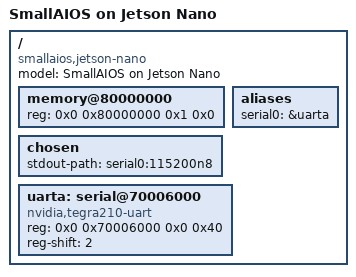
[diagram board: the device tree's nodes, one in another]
// SPDX-License-Identifier: Apache-2.0
// Copyright 2026 SmallAIOS Contributors
//
// Minimal device tree for SmallAIOS on Jetson Nano (Tegra210/T210).
// Written independently from public hardware documentation — NOT derived
// from GPL-licensed Linux kernel or NVIDIA L4T BSP DTS files.
//
// Sources:
//   - ARM Architecture Reference Manual (ARMv8-A)
//   - ARM GIC-400 Technical Reference Manual (ARM IHI 0048B)
//   - ARM Cortex-A57 Technical Reference Manual (ARM DDI 0488)
//   - Jetson Nano Developer Kit carrier board design files (public)
//   - eLinux.org Jetson/Nano wiki

/dts-v1/;

/ {
    compatible = "smallaios,jetson-nano", "nvidia,tegra210";
    model = "SmallAIOS on Jetson Nano";
    #address-cells = <2>;
    #size-cells = <2>;

    memory@80000000 {
        device_type = "memory";
        reg = <0x0 0x80000000 0x1 0x0>;  // 4 GiB @ 0x80000000
    };

    chosen {
        stdout-path = "serial0:115200n8";
    };

    // Aliases for U-Boot console selection
    aliases {
        serial0 = &uarta;
    };

    // UART-A (NS16550A compatible, pre-initialized by U-Boot)
    uarta: serial@70006000 {
        compatible = "nvidia,tegra210-uart", "ns16550a";
        reg = <0x0 0x70006000 0x0 0x40>;
        reg-shift = <2>;
        status = "okay";
    };
};
